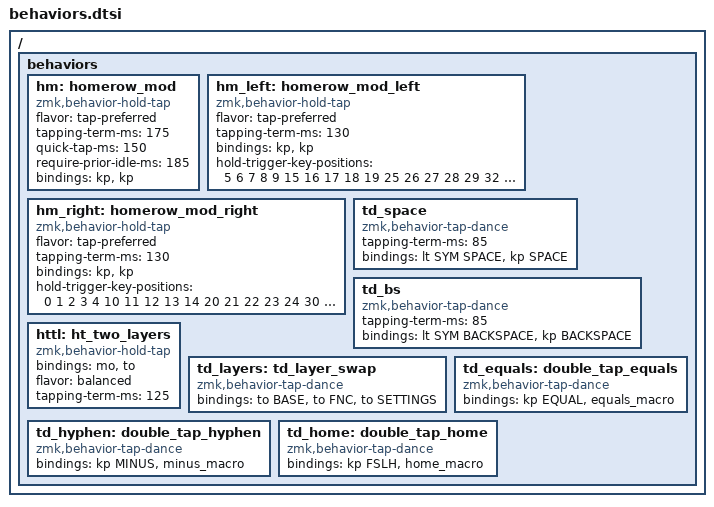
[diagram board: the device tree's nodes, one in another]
/ {
	behaviors {
		hm: homerow_mod {
			compatible = "zmk,behavior-hold-tap";
			#binding-cells = <2>;
			flavor = "tap-preferred";
			tapping-term-ms = <175>;
			quick-tap-ms = <150>;
			require-prior-idle-ms = <185>;
			bindings = <&kp>, <&kp>;
		};

		hm_left: homerow_mod_left {
			compatible = "zmk,behavior-hold-tap";
			#binding-cells = <2>;
			flavor = "tap-preferred";
			tapping-term-ms = <130>;
			bindings = <&kp>, <&kp>;
			hold-trigger-key-positions = <5 6 7 8 9 15 16 17 18 19 25 26 27 28 29 32 33>;
		};

		hm_right: homerow_mod_right {
			compatible = "zmk,behavior-hold-tap";
			#binding-cells = <2>;
			flavor = "tap-preferred";
			tapping-term-ms = <130>;
			bindings = <&kp>, <&kp>;
			hold-trigger-key-positions = <0 1 2 3 4 10 11 12 13 14 20 21 22 23 24 30 31>;
		};

		td_space: td_space {
			compatible = "zmk,behavior-tap-dance";
			#binding-cells = <0>;
			tapping-term-ms = <85>;
			bindings = <&lt SYM SPACE>, <&kp SPACE>;
		};

		td_bs: td_bs {
			compatible = "zmk,behavior-tap-dance";
			#binding-cells = <0>;
			tapping-term-ms = <85>;
			bindings = <&lt SYM BACKSPACE>, <&kp BACKSPACE>;
		};

		httl: ht_two_layers {
			compatible = "zmk,behavior-hold-tap";
			bindings = <&mo>, <&to>;
			#binding-cells = <2>;
			flavor = "balanced";
			tapping-term-ms = <125>;
		};

		td_layers: td_layer_swap {
			compatible = "zmk,behavior-tap-dance";
			#binding-cells = <0>;
			bindings = <&to BASE>, <&to FNC>, <&to SETTINGS>;
		};

		td_hyphen: double_tap_hyphen {
			compatible = "zmk,behavior-tap-dance";
			#binding-cells = <0>;
			bindings = <&kp MINUS>, <&minus_macro>;
		};

		td_equals: double_tap_equals {
			compatible = "zmk,behavior-tap-dance";
			#binding-cells = <0>;
			bindings = <&kp EQUAL>, <&equals_macro>;
		};

		td_home: double_tap_home {
			compatible = "zmk,behavior-tap-dance";
			#binding-cells = <0>;
			bindings = <&kp FSLH>, <&home_macro>;
		};
	};
};
